# nrf54h20_engb_application register map
Vendor: Nordic Semiconductor; Series: nRF54h; File version: 1
CPU: CM33 r0p4, little endian, MPU, FPU, 3 interrupt priority bits, 480 interrupts, 8 SAU regions
Registers are 32-bit, read-write, reset 0x0 unless marked. A register's access mark holds for its fields unless they carry their own. Offsets are from the block's base; [hi:lo] are bit positions; lines under a group give offsets from that group; {n}, {i} and the like mark numbered series; 'fields as' and 'values as' point back to an identical list; <NAME> marks a mode.

## GLOBAL_COMP_NS — Comparator 0
Base 0x4F983000
Same registers: GLOBAL_COMP_S 0x5F983000
0x00 TASKS_START wo — Start comparator
  [0] TASKS_START
    1=Trigger task
0x04 TASKS_STOP wo — Stop comparator
  [0] TASKS_STOP
    1=Trigger task
0x08 TASKS_SAMPLE wo — Sample comparator value. This task requires that COMP has been started by the START Task.
  [0] TASKS_SAMPLE
    1=Trigger task
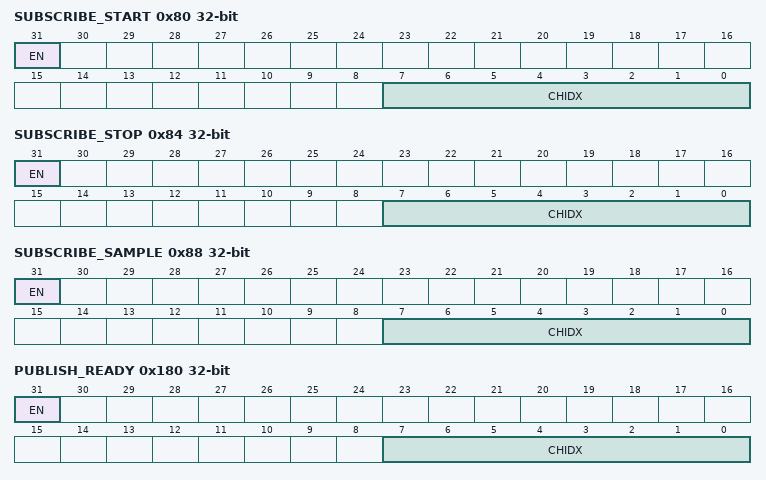
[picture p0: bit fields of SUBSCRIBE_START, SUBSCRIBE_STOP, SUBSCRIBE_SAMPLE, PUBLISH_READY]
0x80 SUBSCRIBE_START — Subscribe configuration for task START
  [31] EN
    0=Disabled (Disable subscription); 1=Enabled (Enable subscription)
  [7:0] CHIDX — DPPI channel that task START will subscribe to
0x84 SUBSCRIBE_STOP — Subscribe configuration for task STOP
  [31] EN
    values as SUBSCRIBE_START.EN
  [7:0] CHIDX — DPPI channel that task STOP will subscribe to
0x88 SUBSCRIBE_SAMPLE — Subscribe configuration for task SAMPLE
  [31] EN
    values as SUBSCRIBE_START.EN
  [7:0] CHIDX — DPPI channel that task SAMPLE will subscribe to
0x100 EVENTS_READY — COMP is ready and output is valid
  [0] EVENTS_READY
    0=NotGenerated (Event not generated); 1=Generated (Event generated)
0x104 EVENTS_DOWN — Downward crossing
  [0] EVENTS_DOWN
    values as EVENTS_READY.EVENTS_READY
0x108 EVENTS_UP — Upward crossing
  [0] EVENTS_UP
    values as EVENTS_READY.EVENTS_READY
0x10C EVENTS_CROSS — Downward or upward crossing
  [0] EVENTS_CROSS
    values as EVENTS_READY.EVENTS_READY
0x180 PUBLISH_READY — Publish configuration for event READY
  [31] EN
    0=Disabled (Disable publishing); 1=Enabled (Enable publishing)
  [7:0] CHIDX — DPPI channel that event READY will publish to
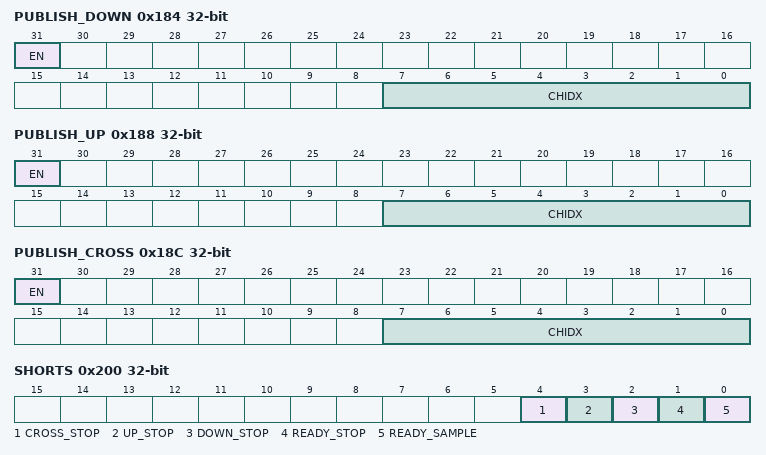
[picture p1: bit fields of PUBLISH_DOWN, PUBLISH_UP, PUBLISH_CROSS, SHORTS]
0x184 PUBLISH_DOWN — Publish configuration for event DOWN
  [31] EN
    values as PUBLISH_READY.EN
  [7:0] CHIDX — DPPI channel that event DOWN will publish to
0x188 PUBLISH_UP — Publish configuration for event UP
  [31] EN
    values as PUBLISH_READY.EN
  [7:0] CHIDX — DPPI channel that event UP will publish to
0x18C PUBLISH_CROSS — Publish configuration for event CROSS
  [31] EN
    values as PUBLISH_READY.EN
  [7:0] CHIDX — DPPI channel that event CROSS will publish to
0x200 SHORTS — Shortcuts between local events and tasks
  [all] fields
    0=Disabled (Disable shortcut); 1=Enabled (Enable shortcut)
  [4] CROSS_STOP — Shortcut between event CROSS and task STOP
  [3] UP_STOP — Shortcut between event UP and task STOP
  [2] DOWN_STOP — Shortcut between event DOWN and task STOP
  [1] READY_STOP — Shortcut between event READY and task STOP
  [0] READY_SAMPLE — Shortcut between event READY and task SAMPLE
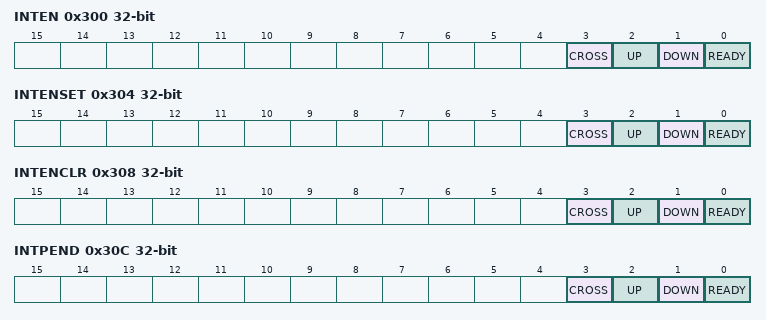
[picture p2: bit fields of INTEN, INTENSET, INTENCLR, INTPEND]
0x300 INTEN — Enable or disable interrupt
  [all] fields
    0=Disabled; 1=Enabled
  [3] CROSS — Enable or disable interrupt for event CROSS
  [2] UP — Enable or disable interrupt for event UP
  [1] DOWN — Enable or disable interrupt for event DOWN
  [0] READY — Enable or disable interrupt for event READY
0x304 INTENSET — Enable interrupt
  [all] fields
    on read: 0=Disabled (Read: Disabled); 1=Enabled (Read: Enabled) | on write: 1=Set (Enable)
  [3] CROSS — Write '1' to enable interrupt for event CROSS
  [2] UP — Write '1' to enable interrupt for event UP
  [1] DOWN — Write '1' to enable interrupt for event DOWN
  [0] READY — Write '1' to enable interrupt for event READY
0x308 INTENCLR — Disable interrupt
  [all] fields
    on read: 0=Disabled (Read: Disabled); 1=Enabled (Read: Enabled) | on write: 1=Clear (Disable)
  [3] CROSS — Write '1' to disable interrupt for event CROSS
  [2] UP — Write '1' to disable interrupt for event UP
  [1] DOWN — Write '1' to disable interrupt for event DOWN
  [0] READY — Write '1' to disable interrupt for event READY
0x30C INTPEND ro — Pending interrupts
  [all] fields
    on read: 0=NotPending (Read: Not pending); 1=Pending (Read: Pending)
  [3] CROSS — Read pending status of interrupt for event CROSS
  [2] UP — Read pending status of interrupt for event UP
  [1] DOWN — Read pending status of interrupt for event DOWN
  [0] READY — Read pending status of interrupt for event READY
0x400 RESULT ro — Compare result
  [0] RESULT — Result of last compare. Decision point SAMPLE task.
    0=Below (Input voltage is below the threshold (VIN+ < VIN-)); 1=Above (Input voltage is above the threshold (VIN+ > VIN-))
0x404 BGREADY ro — COMP module is ready
  [0] STATE — Result of last compare. Decision point SAMPLE task.
    0=NotReady (Module is not ready); 1=Ready (Module is ready)
0x500 ENABLE — COMP enable
  [1:0] ENABLE — Enable or disable COMP
    0=Disabled; 2=Enabled
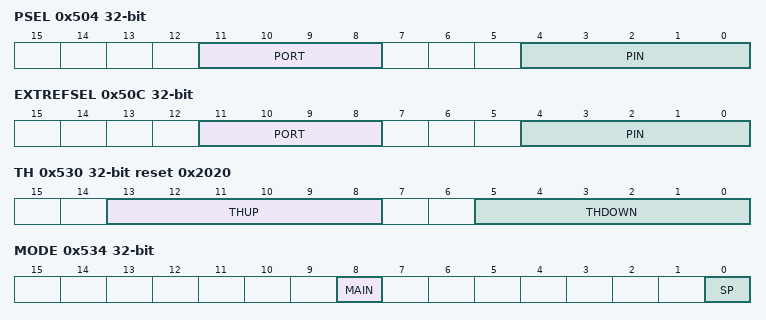
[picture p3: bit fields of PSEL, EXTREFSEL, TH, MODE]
0x504 PSEL — Pin select
  [11:8] PORT — GPIO Port selection
  [4:0] PIN — Analog pin select
0x508 REFSEL reset 0x4 — Reference source select for single-ended mode
  [2:0] REFSEL — Reference select
    0=Int1V2 (VREF = internal 1.2 V reference); 1=Int1V8 (VREF = internal 1.8 V reference (VDD >= VREF + 0.2 V)); 2=Int2V4 (VREF = internal 2.4 V reference (VDD >= VREF + 0.2 V)); 4=AVDDAO1V8 (VREF = internal 1.8 V reference); 5=ARef (VREF = AREF); 7=Diff (VREF = Differential mode (power down built-in reference and disconnect resistor ladder))
0x50C EXTREFSEL — External reference select
  [11:8] PORT — GPIO Port selection
  [4:0] PIN — External analog reference pin select
0x510 REFTEMPC — Trim for temperature coefficient
  [3:0] REFTEMPC — Trim for temperature coefficient in 2's complement. Used to compensate between simulation and measurement
0x514 BUFFER — Enable unity gain buffer
  [0] BUFFER
    0=Disable (VOUT is high impedance); 1=Enable (VOUT equals VIN)
0x524 RETAIN — Retain signal
  [0] RETAIN — Retain signal, shared for both COMP and LPCOMP
    0=Disable (No retain); 1=Enable (Retain is active)
0x530 TH reset 0x2020 — Threshold configuration for hysteresis unit
  [13:8] THUP — VUP = (THUP+1)/64*VREF
  [5:0] THDOWN — VDOWN = (THDOWN+1)/64*VREF
0x534 MODE — Mode configuration
  [8] MAIN — Main operation modes
    0=SE (Single-ended mode); 1=Differential mode
  [0] SP — Speed and power modes
    0=Low (Low-power mode); 1=High-speed mode
0x538 HYST — Comparator hysteresis enable
  [0] HYST — Comparator hysteresis
    0=NoHyst (Comparator hysteresis disabled); 1=Hyst40mV (Comparator hysteresis enabled)
0x53C ISOURCE — Current source select on analog input
  [1:0] ISOURCE
    0=Off (Current source disabled); 1=Ien2uA5 (Current source enabled (+/- 2.5 uA)); 2=Ien5uA (Current source enabled (+/- 5 uA)); 3=Ien10uA (Current source enabled (+/- 10 uA))
0x540 REFTRIM — Trim internal band gap reference
  [4:0] REFTRIM — Trimming value in 2's complement
0x580 OVERRIDE group — Unspecified
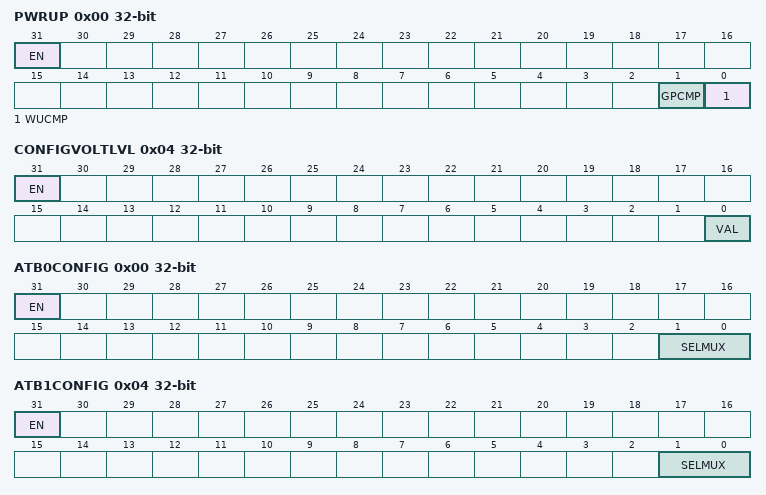
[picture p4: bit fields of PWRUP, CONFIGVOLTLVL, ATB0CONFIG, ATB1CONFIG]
  0x00 PWRUP — Override the PWRUP signals to the analog modules
    [31] EN — Enable the overrides
      0=Disabled (Overrides are disabled); 1=Enabled (Overrides are enabled)
    [1] GPCMP — Override value for PWRUP_GPCMP_AO_0V8
    [0] WUCMP — Override value for PWRUP_LPCMP_AO_0V8
  0x04 CONFIGVOLTLVL — Override LPCMP_INSEL_RET_0V8 and GPCMP_CTRL_RET_0V8[0]
    [31] EN — Enable the override
      0=Disabled (Override is disabled); 1=Enabled (Override is enabled)
    [0] VAL — Override value for the signal
0x600 DFT group — Unspecified
  0x00 ATB0CONFIG — Unspecified
    [31] EN
    [1:0] SELMUX — Select multiplexer for ATB0
      {v}=Config{v} (Configuration {v} selected) (v=0..3)
  0x04 ATB1CONFIG — Unspecified
    [31] EN
    [1:0] SELMUX — Select multiplexer for ATB1
      {v}=Config{v} (Configuration {v} selected) (v=0..3)
  0x08 ATB2CONFIG — Unspecified
    [31] EN
      0=Config0 (Configuration 0 selected); 1=Config1 (Configuration 1 selected)
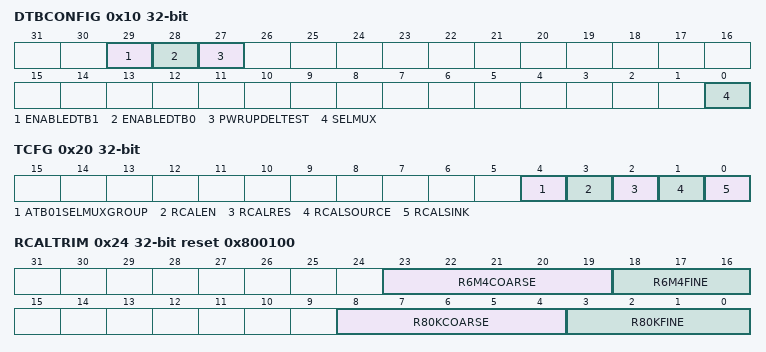
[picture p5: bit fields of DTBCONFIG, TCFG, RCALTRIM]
  0x10 DTBCONFIG — Digital Test Bus (DTB0-3) configuration
    [29] ENABLEDTB1 — Enable the digital test bus
      0=Disabled (Digital test bus is disabled); 1=Enabled (Digital test bus is enabled)
    [28] ENABLEDTB0 — Enable the digital test bus 0 (DTB0)
      values as ENABLEDTB1
    [27] PWRUPDELTEST — Enable the PWRUP delay test circuit on DTB3
      0=Disabled (PWRUP delay test circuit is disabled); 1=Enabled (PWRUP delay test circuit is enabled)
    [0] SELMUX — Select multiplexer for DTB0
      0=Config0 (Configuration 0 selected)
  0x20 TCFG — Test configuration
    [4] ATB01SELMUXGROUP — Select multiplexer group for ATB0-1
      0=Group0 (Multiplexer group 0); 1=Group1 (Multiplexer group 1)
    [3] RCALEN
      0=Disabled (Resistor calibration disabled); 1=Enabled (Resistor calibration enabled)
    [2] RCALRES
      0=Res80K (Select 80k resistor); 1=Res6M4 (Select 6.4M resistor)
    [1] RCALSOURCE
      0=Top (Tap voltage from top of resistor); 1=Bottom (Tap voltage from bottom of resistor)
    [0] RCALSINK
      0=Vip (Output voltage to inverting input (VIP)); 1=Vin (Output voltage to non-inverting input (VIN))
  0x24 RCALTRIM reset 0x800100 — Trimming values for RCAL
    [23:19] R6M4COARSE — Coarse trim of 6.4M resistor (2's complement)
    [18:16] R6M4FINE — Fine trim of 6.4M resistor, max stepsize less than 2.5 percent (not 2's complement)
    [8:4] R80KCOARSE — Coarse trim of 80k resistor (2's complement)
    [3:0] R80KFINE — Fine trim of 80k resistor, max stepsize less than 0.67 percent (not 2's complement)

## GLOBAL_LPCOMP_NS — Low-power comparator 0
Base 0x4F983000; alternate view of GLOBAL_COMP_NS
Same registers: GLOBAL_LPCOMP_S 0x5F983000 (alternate view of GLOBAL_COMP_S)
Registers as GLOBAL_COMP_NS, without BGREADY, REFTEMPC, BUFFER, TH, MODE, ISOURCE, REFTRIM; these are added or differ:
0x08 TASKS_SAMPLE wo — Sample comparator value
  [0] TASKS_SAMPLE
    1=Trigger task
0x100 EVENTS_READY — LPCOMP is ready and output is valid
  [0] EVENTS_READY
    0=NotGenerated (Event not generated); 1=Generated (Event generated)
0x400 RESULT ro — Compare result
  [0] RESULT — Result of last compare. Decision point SAMPLE task.
    0=Below (Input voltage is below the reference threshold (VIN+ < VIN-)); 1=Above (Input voltage is above the reference threshold (VIN+ > VIN-))
0x500 ENABLE — Enable LPCOMP
  [1:0] ENABLE — Enable or disable LPCOMP
    0=Disabled; 1=Enabled
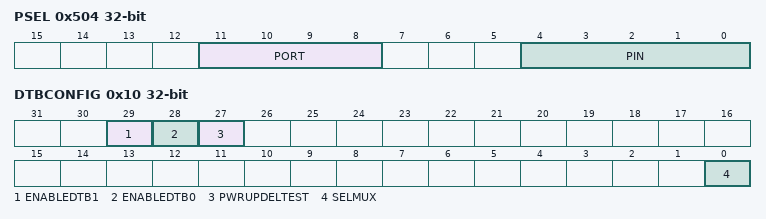
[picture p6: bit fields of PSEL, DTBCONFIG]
0x504 PSEL — Input pin select
  [11:8] PORT — GPIO Port selection
  [4:0] PIN — Analog pin select
0x508 REFSEL reset 0x4 — Reference select
  [3:0] REFSEL
    {v}=Ref{v+1}_8Vdd (VDD * {v+1}/8 selected as reference) (v=0..6); 7=ARef (External analog reference selected); 8=Ref1_16Vdd (VDD * 1/16 selected as reference); 9=Ref3_16Vdd (VDD * 3/16 selected as reference); 10=Ref5_16Vdd (VDD * 5/16 selected as reference); 11=Ref7_16Vdd (VDD * 7/16 selected as reference); 12=Ref9_16Vdd (VDD * 9/16 selected as reference); 13=Ref11_16Vdd (VDD * 11/16 selected as reference); 14=Ref13_16Vdd (VDD * 13/16 selected as reference); 15=Ref15_16Vdd (VDD * 15/16 selected as reference)
0x520 ANADETECT — Analog detect configuration
  [1:0] ANADETECT
    0=Cross (Generate ANADETECT on crossing, both upward crossing and downward crossing); 1=Up (Generate ANADETECT on upward crossing only); 2=Down (Generate ANADETECT on downward crossing only)
0x524 RETAIN — Retain signal
  [0] RETAIN
    0=Disable (No retain); 1=Enable (Retain is active)
0x538 HYST — Comparator hysteresis enable
  [0] HYST
    0=Disabled (Comparator hysteresis disabled); 1=Enabled (Comparator hysteresis enabled)
0x600 DFT group — Unspecified
  0x00 ATB0CONFIG — Analog Test Bus 0 (ATB0) configuration
    [31] EN — Enable the analog test bus
      0=Disabled (Analog test bus is disabled); 1=Enabled (Analog test bus is enabled)
  0x10 DTBCONFIG — Digital Test Bus (DTB0-3) configuration
    [29] ENABLEDTB1 — Enable the digital test bus
      0=Disabled (Digital test bus is disabled); 1=Enabled (Digital test bus is enabled)
    [28] ENABLEDTB0 — Enable the digital test bus 0 (DTB0)
      values as ENABLEDTB1
    [27] PWRUPDELTEST — Enable the PWRUP delay test circuit on DTB3
      0=Disabled (PWRUP delay test circuit is disabled); 1=Enabled (PWRUP delay test circuit is enabled)
    [0] SELMUX — Select multiplexer for DTB0
      0=Config0 (Configuration 0 selected); 1=Config1 (Configuration 1 selected)
